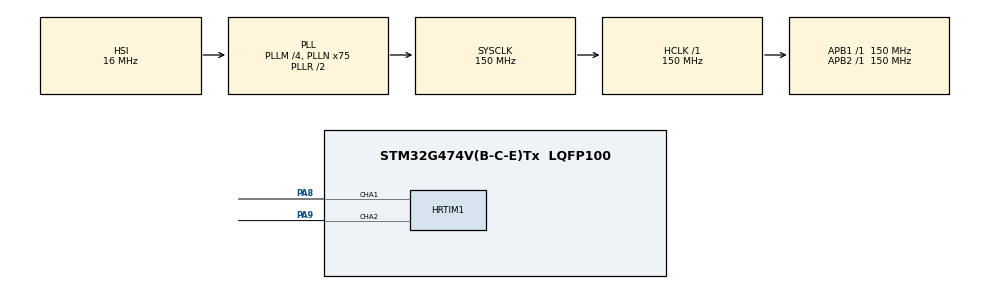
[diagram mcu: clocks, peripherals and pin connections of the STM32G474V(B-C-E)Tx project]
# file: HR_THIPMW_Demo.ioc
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HRTIM1.CompareUnit1-Output_TA1TA2=HRTIM_COMPAREUNIT_1
HRTIM1.CompareValue1-Output_TA1TA2=30000
HRTIM1.DeadTimeInsertion-Output_TA1TA2=HRTIM_TIMDEADTIMEINSERTION_ENABLED
HRTIM1.FallingValue-Output_TA1TA2=100
HRTIM1.InterruptRequests1-Output_TA1TA2=HRTIM_TIM_IT_REP
HRTIM1.NumberInterruptRequests-Output_TA1TA2=1
HRTIM1.NumberResetSource1-Output_TA1TA2=1
HRTIM1.NumberSetSource1-Output_TA1TA2=1
HRTIM1.Periode_TA=60000
HRTIM1.PreloadEnable-Output_TA1TA2=HRTIM_PRELOAD_ENABLED
HRTIM1.PrescalerDead-Output_TA1TA2=HRTIM_TIMDEADTIME_PRESCALERRATIO_DIV1
HRTIM1.PrescalerRatio_TA=HRTIM_PRESCALERRATIO_MUL8
HRTIM1.RepetitionUpdate-Output_TA1TA2=HRTIM_UPDATEONREPETITION_ENABLED
HRTIM1.ResetOutput1_Source1-Output_TA1TA2=HRTIM_OUTPUTRESET_TIMCMP1
HRTIM1.RisingValue-Output_TA1TA2=100
HRTIM1.SetOutput1_Source1-Output_TA1TA2=HRTIM_OUTPUTSET_TIMPER
Mcu.Family=STM32G4
Mcu.Name=STM32G474V(B-C-E)Tx
Mcu.Package=LQFP100
NVIC.HRTIM1_TIMA_IRQn=true\:0\:0\:false\:false\:true\:true\:true\:true
NVIC.PriorityGroup=NVIC_PRIORITYGROUP_4
PA8.Mode=Output_TA1TA2
PA8.Signal=HRTIM1_CHA1
PA9.Mode=Output_TA1TA2
PA9.Signal=HRTIM1_CHA2
PC14-OSC32_IN.Mode=LSE-External-Oscillator
PC14-OSC32_IN.Signal=RCC_OSC32_IN
PC15-OSC32_OUT.Mode=LSE-External-Oscillator
PC15-OSC32_OUT.Signal=RCC_OSC32_OUT
PF0-OSC_IN.Mode=HSE-External-Oscillator
PF0-OSC_IN.Signal=RCC_OSC_IN
PF1-OSC_OUT.Mode=HSE-External-Oscillator
PF1-OSC_OUT.Signal=RCC_OSC_OUT
ProjectManager.HeapSize=0x200
ProjectManager.StackSize=0x400
ProjectManager.TargetToolchain=MDK-ARM V5.32
RCC.ADC12Freq_Value=150000000
RCC.ADC345Freq_Value=150000000
RCC.AHBFreq_Value=150000000
RCC.APB1Freq_Value=150000000
RCC.APB1TimFreq_Value=150000000
RCC.APB2Freq_Value=150000000
RCC.APB2TimFreq_Value=150000000
RCC.CortexFreq_Value=150000000
RCC.EXTERNAL_CLOCK_VALUE=12288000
RCC.HCLKFreq_Value=150000000
RCC.HSE_VALUE=8000000
RCC.HSI48_VALUE=48000000
RCC.HSI_VALUE=16000000
RCC.PLLM=RCC_PLLM_DIV4
RCC.PLLN=75
RCC.SYSCLKFreq_VALUE=150000000
RCC.SYSCLKSource=RCC_SYSCLKSOURCE_PLLCLK
RCC.USBFreq_Value=150000000
RCC.VCOOutputFreq_Value=300000000
STMicroelectronics.X-CUBE-ALGOBUILD.1.4.0.LibraryCcDSPOoLibraryJjDSPOoLibrary=true
VP_STMicroelectronics.X-CUBE-ALGOBUILD_VS_DSPOoLibraryJjLibrary_1.4.0_1.4.0.Mode=DSPOoLibraryJjLibrary
VP_SYS_VS_DBSignals.Mode=DisableDeadBatterySignals
board=custom

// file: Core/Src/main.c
/* USER CODE BEGIN Header */
/**
  ******************************************************************************
  * @file           : main.c
  * @brief          : Main program body
  ******************************************************************************
  * @attention
  *
  * Copyright (c) 2025 STMicroelectronics.
  * All rights reserved.
  *
  * This software is licensed under terms that can be found in the LICENSE file
  * in the root directory of this software component.
  * If no LICENSE file comes with this software, it is provided AS-IS.
  *
  ******************************************************************************
  */
/* USER CODE END Header */
#include "main.h"
#include "hrtim.h"
#include "gpio.h"

/* USER CODE BEGIN Includes */
#include "arm_math.h"
/* USER CODE END Includes */

void SystemClock_Config(void);

/* USER CODE BEGIN 0 */

float sin_temp = 0;
float P_temp = 1.0f;
uint16_t cnt_temp = 0;

/* USER CODE END 0 */

int main(void)
{

  /* MCU Configuration--------------------------------------------------------*/

  /* Reset of all peripherals, Initializes the Flash interface and the Systick. */
  HAL_Init();

  /* Configure the system clock */
  SystemClock_Config();

  /* Initialize all configured peripherals */
  MX_GPIO_Init();
  MX_HRTIM1_Init();
  /* USER CODE BEGIN 2 */

	HAL_HRTIM_WaveformCounterStart_IT(&hhrtim1,HRTIM_TIMERID_TIMER_A);
	HAL_HRTIM_WaveformOutputStart(&hhrtim1,HRTIM_OUTPUT_TA1 | HRTIM_OUTPUT_TA2);

  /* USER CODE END 2 */

  /* Infinite loop */
  while (1)
  {

  }
}

void SystemClock_Config(void)
{
  RCC_OscInitTypeDef RCC_OscInitStruct = {0};
  RCC_ClkInitTypeDef RCC_ClkInitStruct = {0};

  /** Configure the main internal regulator output voltage
  */
  HAL_PWREx_ControlVoltageScaling(PWR_REGULATOR_VOLTAGE_SCALE1);

  /** Initializes the RCC Oscillators according to the specified parameters
  * in the RCC_OscInitTypeDef structure.
  */
  RCC_OscInitStruct.OscillatorType = RCC_OSCILLATORTYPE_HSI;
  RCC_OscInitStruct.HSIState = RCC_HSI_ON;
  RCC_OscInitStruct.HSICalibrationValue = RCC_HSICALIBRATION_DEFAULT;
  RCC_OscInitStruct.PLL.PLLState = RCC_PLL_ON;
  RCC_OscInitStruct.PLL.PLLSource = RCC_PLLSOURCE_HSI;
  RCC_OscInitStruct.PLL.PLLM = RCC_PLLM_DIV4;
  RCC_OscInitStruct.PLL.PLLN = 75;
  RCC_OscInitStruct.PLL.PLLP = RCC_PLLP_DIV2;
  RCC_OscInitStruct.PLL.PLLQ = RCC_PLLQ_DIV2;
  RCC_OscInitStruct.PLL.PLLR = RCC_PLLR_DIV2;
  if (HAL_RCC_OscConfig(&RCC_OscInitStruct) != HAL_OK)
  {
    Error_Handler();
  }

  /** Initializes the CPU, AHB and APB buses clocks
  */
  RCC_ClkInitStruct.ClockType = RCC_CLOCKTYPE_HCLK|RCC_CLOCKTYPE_SYSCLK
                              |RCC_CLOCKTYPE_PCLK1|RCC_CLOCKTYPE_PCLK2;
  RCC_ClkInitStruct.SYSCLKSource = RCC_SYSCLKSOURCE_PLLCLK;
  RCC_ClkInitStruct.AHBCLKDivider = RCC_SYSCLK_DIV1;
  RCC_ClkInitStruct.APB1CLKDivider = RCC_HCLK_DIV1;
  RCC_ClkInitStruct.APB2CLKDivider = RCC_HCLK_DIV1;

  if (HAL_RCC_ClockConfig(&RCC_ClkInitStruct, FLASH_LATENCY_4) != HAL_OK)
  {
    Error_Handler();
  }
}

/* USER CODE BEGIN 4 */

void HAL_HRTIM_RepetitionEventCallback(HRTIM_HandleTypeDef *hhrtim,
                                       uint32_t TimerIdx)
{
	if(TimerIdx == HRTIM_TIMERINDEX_TIMER_A)
	{
		sin_temp =1.1547f*arm_sin_f32(1/400.0f*PI*cnt_temp) + 0.19245f*arm_sin_f32(1/400.0f*PI*cnt_temp*3);
		cnt_temp++;
		if(cnt_temp >= 800)
			cnt_temp = 0;

		HRTIM1->sTimerxRegs[HRTIM_TIMERINDEX_TIMER_A].CMP1xR =30000 + P_temp*sin_temp*30000;
	}
}

/* USER CODE END 4 */

void Error_Handler(void)
{
  __disable_irq();
  while (1)
  {
  }
}
